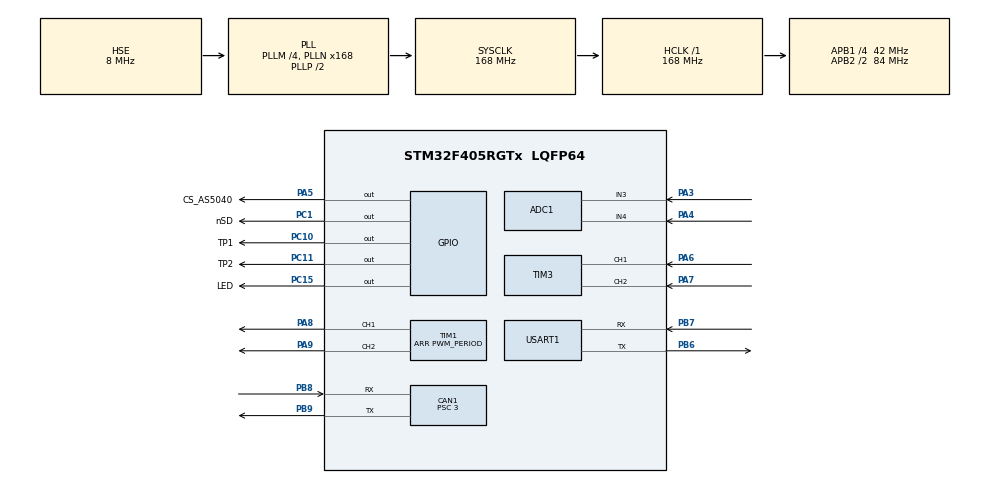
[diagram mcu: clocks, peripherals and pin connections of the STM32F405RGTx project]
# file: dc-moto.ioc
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ADC1.Channel-0\#ChannelRegularConversion=ADC_CHANNEL_3
ADC1.Channel-8\#ChannelInjectedConversion=ADC_CHANNEL_3
ADC1.Channel-9\#ChannelInjectedConversion=ADC_CHANNEL_4
ADC1.ContinuousConvMode=ENABLE
ADC1.DMAContinuousRequests=DISABLE
ADC1.DiscontinuousConvMode=DISABLE
ADC1.EOCSelection=ADC_EOC_SEQ_CONV
ADC1.ExternalTrigConv=ADC_SOFTWARE_START
ADC1.InjNumberOfConversion=2
ADC1.InjectedConvMode=None
ADC1.InjectedOffset-8\#ChannelInjectedConversion=0
ADC1.InjectedOffset-9\#ChannelInjectedConversion=0
ADC1.InjectedRank-8\#ChannelInjectedConversion=1
ADC1.InjectedRank-9\#ChannelInjectedConversion=2
ADC1.NbrOfConversion=1
ADC1.NbrOfConversionFlag=1
ADC1.Rank-0\#ChannelRegularConversion=1
ADC1.SamplingTime-0\#ChannelRegularConversion=ADC_SAMPLETIME_15CYCLES
ADC1.SamplingTime-8\#ChannelInjectedConversion=ADC_SAMPLETIME_3CYCLES
ADC1.SamplingTime-9\#ChannelInjectedConversion=ADC_SAMPLETIME_3CYCLES
ADC1.master=1
CAN1.BS1=CAN_BS1_11TQ
CAN1.BS2=CAN_BS2_2TQ
CAN1.CalculateBaudRate=1000000
CAN1.CalculateTimeBit=999.99
CAN1.CalculateTimeQuantum=71.42857142857143
CAN1.NART=DISABLE
CAN1.Prescaler=3
CAN1.SJW=CAN_SJW_1TQ
Mcu.Family=STM32F4
Mcu.Name=STM32F405RGTx
Mcu.Package=LQFP64
Mcu.UserConstants=PWM_PERIOD,8200;PWM_HALF_PERIOD,4100;ADC_START_TIME,7380
NVIC.CAN1_RX0_IRQn=true\:1\:0\:true\:false\:true\:true\:true
NVIC.PriorityGroup=NVIC_PRIORITYGROUP_4
NVIC.TIM1_CC_IRQn=true\:0\:0\:true\:false\:true\:true\:true
PA13.Mode=Serial_Wire
PA13.Signal=SYS_JTMS-SWDIO
PA14.Mode=Serial_Wire
PA14.Signal=SYS_JTCK-SWCLK
PA3.Signal=ADCx_IN3
PA4.Signal=ADCx_IN4
PA5.GPIO_Label=CS_AS5040
PA5.Signal=GPIO_Output
PA6.Signal=S_TIM3_CH1
PA7.Signal=S_TIM3_CH2
PA8.Signal=S_TIM1_CH1
PA9.Signal=S_TIM1_CH2
PB6.Mode=Asynchronous
PB6.Signal=USART1_TX
PB7.Mode=Asynchronous
PB7.Signal=USART1_RX
PB8.Mode=CAN_Activate
PB8.Signal=CAN1_RX
PB9.Mode=CAN_Activate
PB9.Signal=CAN1_TX
PC1.GPIO_Label=nSD
PC1.GPIO_PuPd=GPIO_PULLDOWN
PC1.GPIO_Speed=GPIO_SPEED_FREQ_VERY_HIGH
PC1.Signal=GPIO_Output
PC10.GPIO_Label=TP1
PC10.GPIO_Speed=GPIO_SPEED_FREQ_VERY_HIGH
PC10.Signal=GPIO_Output
PC11.GPIO_Label=TP2
PC11.GPIO_Speed=GPIO_SPEED_FREQ_VERY_HIGH
PC11.Signal=GPIO_Output
PC15-OSC32_OUT.GPIO_Label=LED
PC15-OSC32_OUT.Signal=GPIO_Output
PH0-OSC_IN.Mode=HSE-External-Oscillator
PH0-OSC_IN.Signal=RCC_OSC_IN
PH1-OSC_OUT.Mode=HSE-External-Oscillator
PH1-OSC_OUT.Signal=RCC_OSC_OUT
ProjectManager.HeapSize=0x400
ProjectManager.StackSize=0x400
ProjectManager.TargetToolchain=MDK-ARM V5.27
RCC.48MHZClocksFreq_Value=84000000
RCC.AHBFreq_Value=168000000
RCC.APB1CLKDivider=RCC_HCLK_DIV4
RCC.APB1Freq_Value=42000000
RCC.APB1TimFreq_Value=84000000
RCC.APB2CLKDivider=RCC_HCLK_DIV2
RCC.APB2Freq_Value=84000000
RCC.APB2TimFreq_Value=168000000
RCC.CortexFreq_Value=168000000
RCC.HCLKFreq_Value=168000000
RCC.HSE_VALUE=8000000
RCC.HSI_VALUE=16000000
RCC.LSE_VALUE=32768
RCC.PLLM=4
RCC.PLLN=168
RCC.PLLSourceVirtual=RCC_PLLSOURCE_HSE
RCC.SYSCLKFreq_VALUE=168000000
RCC.SYSCLKSource=RCC_SYSCLKSOURCE_PLLCLK
RCC.VCOOutputFreq_Value=336000000
SH.ADCx_IN3.0=ADC1_IN3,IN3
SH.ADCx_IN4.0=ADC1_IN4,IN4
SH.S_TIM1_CH1.0=TIM1_CH1,PWM Generation1 CH1
SH.S_TIM1_CH2.0=TIM1_CH2,PWM Generation2 CH2
SH.S_TIM3_CH1.0=TIM3_CH1,Encoder_Interface
SH.S_TIM3_CH2.0=TIM3_CH2,Encoder_Interface
TIM1.Channel-Output\ Compare3\ No\ Output=TIM_CHANNEL_3
TIM1.Channel-PWM\ Generation1\ CH1=TIM_CHANNEL_1
TIM1.Channel-PWM\ Generation2\ CH2=TIM_CHANNEL_2
TIM1.OCFastMode_PWM-PWM\ Generation1\ CH1=TIM_OCFAST_ENABLE
TIM1.OCFastMode_PWM-PWM\ Generation2\ CH2=TIM_OCFAST_ENABLE
TIM1.Period=PWM_PERIOD
TIM1.Pulse-Output\ Compare3\ No\ Output=ADC_START_TIME
TIM3.AutoReloadPreload=TIM_AUTORELOAD_PRELOAD_ENABLE
TIM3.EncoderMode=TIM_ENCODERMODE_TI12
USART1.VirtualMode=VM_ASYNC
VP_TIM1_VS_ClockSourceINT.Mode=Internal
VP_TIM1_VS_no_output3.Mode=Output Compare3 No Output
board=custom

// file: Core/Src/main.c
/* USER CODE BEGIN Header */
/**
  ******************************************************************************
  * @file           : main.c
  * @brief          : Main program body
  ******************************************************************************
  * @attention
  *
  * <h2><center>&copy; Copyright (c) 2020 STMicroelectronics.
  * All rights reserved.</center></h2>
  *
  * This software component is licensed by ST under BSD 3-Clause license,
  * the "License"; You may not use this file except in compliance with the
  * License. You may obtain a copy of the License at:
  *                        opensource.org/licenses/BSD-3-Clause
  *
  ******************************************************************************
  */
/* USER CODE END Header */
#include "main.h"
#include "adc.h"
#include "can.h"
#include "tim.h"
#include "usart.h"
#include "gpio.h"

/* USER CODE BEGIN Includes */
#include "mexo/mexo.h"
/* USER CODE END Includes */

void SystemClock_Config(void);

int main(void)
{

  /* MCU Configuration--------------------------------------------------------*/

  /* Reset of all peripherals, Initializes the Flash interface and the Systick. */
  HAL_Init();

  /* Configure the system clock */
  SystemClock_Config();

  /* Initialize all configured peripherals */
  MX_GPIO_Init();
  MX_USART1_UART_Init();
  MX_TIM1_Init();
  MX_ADC1_Init();
  MX_CAN1_Init();
  MX_TIM3_Init();
  /* USER CODE BEGIN 2 */
	mexo_init();

  /* USER CODE END 2 */

  /* Infinite loop */
  /* USER CODE BEGIN WHILE */
  while (1)
  {
		mexo_backgroundRun();
    /* USER CODE END WHILE */

  }
}

void SystemClock_Config(void)
{
  RCC_OscInitTypeDef RCC_OscInitStruct = {0};
  RCC_ClkInitTypeDef RCC_ClkInitStruct = {0};

  /** Configure the main internal regulator output voltage
  */
  __HAL_RCC_PWR_CLK_ENABLE();
  __HAL_PWR_VOLTAGESCALING_CONFIG(PWR_REGULATOR_VOLTAGE_SCALE1);
  /** Initializes the RCC Oscillators according to the specified parameters
  * in the RCC_OscInitTypeDef structure.
  */
  RCC_OscInitStruct.OscillatorType = RCC_OSCILLATORTYPE_HSE;
  RCC_OscInitStruct.HSEState = RCC_HSE_ON;
  RCC_OscInitStruct.PLL.PLLState = RCC_PLL_ON;
  RCC_OscInitStruct.PLL.PLLSource = RCC_PLLSOURCE_HSE;
  RCC_OscInitStruct.PLL.PLLM = 4;
  RCC_OscInitStruct.PLL.PLLN = 168;
  RCC_OscInitStruct.PLL.PLLP = RCC_PLLP_DIV2;
  RCC_OscInitStruct.PLL.PLLQ = 4;
  if (HAL_RCC_OscConfig(&RCC_OscInitStruct) != HAL_OK)
  {
    Error_Handler();
  }
  /** Initializes the CPU, AHB and APB buses clocks
  */
  RCC_ClkInitStruct.ClockType = RCC_CLOCKTYPE_HCLK|RCC_CLOCKTYPE_SYSCLK
                              |RCC_CLOCKTYPE_PCLK1|RCC_CLOCKTYPE_PCLK2;
  RCC_ClkInitStruct.SYSCLKSource = RCC_SYSCLKSOURCE_PLLCLK;
  RCC_ClkInitStruct.AHBCLKDivider = RCC_SYSCLK_DIV1;
  RCC_ClkInitStruct.APB1CLKDivider = RCC_HCLK_DIV4;
  RCC_ClkInitStruct.APB2CLKDivider = RCC_HCLK_DIV2;

  if (HAL_RCC_ClockConfig(&RCC_ClkInitStruct, FLASH_LATENCY_5) != HAL_OK)
  {
    Error_Handler();
  }
}

void Error_Handler(void)
{
}

/************************ (C) COPYRIGHT STMicroelectronics *****END OF FILE****/
